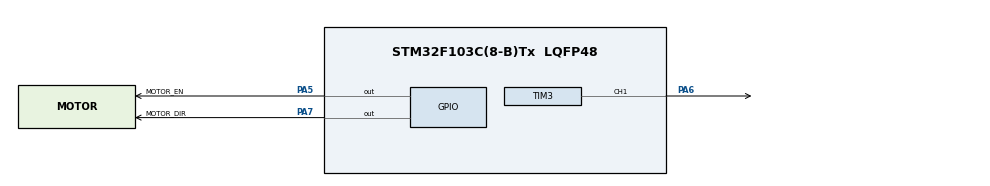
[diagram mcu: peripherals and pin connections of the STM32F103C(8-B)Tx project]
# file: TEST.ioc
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Mcu.Family=STM32F1
Mcu.Name=STM32F103C(8-B)Tx
Mcu.Package=LQFP48
NVIC.PriorityGroup=NVIC_PRIORITYGROUP_4
NVIC.TIM3_IRQn=true\:0\:0\:false\:false\:true\:true\:true\:true
PA13.Mode=Serial_Wire
PA13.Signal=SYS_JTMS-SWDIO
PA14.Mode=Serial_Wire
PA14.Signal=SYS_JTCK-SWCLK
PA5.GPIO_Label=MOTOR_EN
PA5.GPIO_Speed=GPIO_SPEED_FREQ_HIGH
PA5.Signal=GPIO_Output
PA6.Signal=S_TIM3_CH1
PA7.GPIO_Label=MOTOR_DIR
PA7.GPIO_Speed=GPIO_SPEED_FREQ_HIGH
PA7.Signal=GPIO_Output
ProjectManager.HeapSize=0x200
ProjectManager.StackSize=0x400
ProjectManager.TargetToolchain=CMake
RCC.APB1Freq_Value=8000000
RCC.APB2Freq_Value=8000000
SH.S_TIM3_CH1.0=TIM3_CH1,PWM Generation1 CH1
TIM3.Channel-PWM\ Generation1\ CH1=TIM_CHANNEL_1
TIM3.Period=10000
TIM3.Prescaler=71
VP_TIM3_VS_ClockSourceINT.Mode=Internal
board=custom

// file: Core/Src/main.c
/* USER CODE BEGIN Header */
/**
  ******************************************************************************
  * @file           : main.c
  * @brief          : Main program body
  ******************************************************************************
  * @attention
  *
  * Copyright (c) 2026 STMicroelectronics.
  * All rights reserved.
  *
  * This software is licensed under terms that can be found in the LICENSE file
  * in the root directory of this software component.
  * If no LICENSE file comes with this software, it is provided AS-IS.
  *
  ******************************************************************************
  */
/* USER CODE END Header */
#include "main.h"
#include "stepper_motor.h"

/* USER CODE BEGIN PD */
extern volatile uint8_t is_motor_running;
/* USER CODE END PD */

TIM_HandleTypeDef htim3;

void SystemClock_Config(void);
static void MX_GPIO_Init(void);
static void MX_TIM3_Init(void);

int main(void)
{

  /* MCU Configuration--------------------------------------------------------*/

  /* Reset of all peripherals, Initializes the Flash interface and the Systick. */
  HAL_Init();

  /* Configure the system clock */
  SystemClock_Config();

  /* Initialize all configured peripherals */
  MX_GPIO_Init();
  MX_TIM3_Init();
  /* USER CODE BEGIN 2 */
  Motor_Stop();
  HAL_Delay(1000);
  /* USER CODE END 2 */

  /* Infinite loop */
  /* USER CODE BEGIN WHILE */
  while (1)
  {
    // --- 第 1 次转动：顺时针转 2 圈 (720 度) ---
    // 速度设定 360 度/秒，那么 2 圈大约跑 2 秒
    Motor_Speed_Dir_Angle(360.0f, 1, 720.0f);

    // 等待电机自动停止 (is_motor_running 被中断清 0)
    // 加上 100ms 的额外保护，避免刚好卡在临界点
    while (is_motor_running) {
        HAL_Delay(10);
    }
    HAL_Delay(100);

    // --- 停顿 2 秒 ---
    Motor_Stop(); // 确保完全停止
    HAL_Delay(2000);

    // --- 第 2 次转动：逆时针转 2 圈 (720 度) ---
    Motor_Speed_Dir_Angle(360.0f, 0, 720.0f);

    // 再次等待转动结束
    while (is_motor_running) {
        HAL_Delay(10);
    }
    HAL_Delay(100);

    // --- 停顿 2 秒，然后自动进入下一次循环 ---
    Motor_Stop();
    HAL_Delay(2000);
    /* USER CODE END WHILE */

  }
}

void SystemClock_Config(void)
{
  RCC_OscInitTypeDef RCC_OscInitStruct = {0};
  RCC_ClkInitTypeDef RCC_ClkInitStruct = {0};

  /** Initializes the RCC Oscillators according to the specified parameters
  * in the RCC_OscInitTypeDef structure.
  */
  RCC_OscInitStruct.OscillatorType = RCC_OSCILLATORTYPE_HSI;
  RCC_OscInitStruct.HSIState = RCC_HSI_ON;
  RCC_OscInitStruct.HSICalibrationValue = RCC_HSICALIBRATION_DEFAULT;
  RCC_OscInitStruct.PLL.PLLState = RCC_PLL_NONE;
  if (HAL_RCC_OscConfig(&RCC_OscInitStruct) != HAL_OK)
  {
    Error_Handler();
  }

  /** Initializes the CPU, AHB and APB buses clocks
  */
  RCC_ClkInitStruct.ClockType = RCC_CLOCKTYPE_HCLK|RCC_CLOCKTYPE_SYSCLK
                              |RCC_CLOCKTYPE_PCLK1|RCC_CLOCKTYPE_PCLK2;
  RCC_ClkInitStruct.SYSCLKSource = RCC_SYSCLKSOURCE_HSI;
  RCC_ClkInitStruct.AHBCLKDivider = RCC_SYSCLK_DIV1;
  RCC_ClkInitStruct.APB1CLKDivider = RCC_HCLK_DIV1;
  RCC_ClkInitStruct.APB2CLKDivider = RCC_HCLK_DIV1;

  if (HAL_RCC_ClockConfig(&RCC_ClkInitStruct, FLASH_LATENCY_0) != HAL_OK)
  {
    Error_Handler();
  }
}

static void MX_TIM3_Init(void)
{

  TIM_ClockConfigTypeDef sClockSourceConfig = {0};
  TIM_MasterConfigTypeDef sMasterConfig = {0};
  TIM_OC_InitTypeDef sConfigOC = {0};

  htim3.Instance = TIM3;
  htim3.Init.Prescaler = 71;
  htim3.Init.CounterMode = TIM_COUNTERMODE_UP;
  htim3.Init.Period = 10000;
  htim3.Init.ClockDivision = TIM_CLOCKDIVISION_DIV1;
  htim3.Init.AutoReloadPreload = TIM_AUTORELOAD_PRELOAD_DISABLE;
  if (HAL_TIM_Base_Init(&htim3) != HAL_OK)
  {
    Error_Handler();
  }
  sClockSourceConfig.ClockSource = TIM_CLOCKSOURCE_INTERNAL;
  if (HAL_TIM_ConfigClockSource(&htim3, &sClockSourceConfig) != HAL_OK)
  {
    Error_Handler();
  }
  if (HAL_TIM_PWM_Init(&htim3) != HAL_OK)
  {
    Error_Handler();
  }
  sMasterConfig.MasterOutputTrigger = TIM_TRGO_RESET;
  sMasterConfig.MasterSlaveMode = TIM_MASTERSLAVEMODE_DISABLE;
  if (HAL_TIMEx_MasterConfigSynchronization(&htim3, &sMasterConfig) != HAL_OK)
  {
    Error_Handler();
  }
  sConfigOC.OCMode = TIM_OCMODE_PWM1;
  sConfigOC.Pulse = 0;
  sConfigOC.OCPolarity = TIM_OCPOLARITY_HIGH;
  sConfigOC.OCFastMode = TIM_OCFAST_DISABLE;
  if (HAL_TIM_PWM_ConfigChannel(&htim3, &sConfigOC, TIM_CHANNEL_1) != HAL_OK)
  {
    Error_Handler();
  }
  HAL_TIM_MspPostInit(&htim3);

}

static void MX_GPIO_Init(void)
{
  GPIO_InitTypeDef GPIO_InitStruct = {0};

  /* GPIO Ports Clock Enable */
  __HAL_RCC_GPIOA_CLK_ENABLE();

  /*Configure GPIO pin Output Level */
  HAL_GPIO_WritePin(GPIOA, MOTOR_EN_Pin|MOTOR_DIR_Pin, GPIO_PIN_RESET);

  /*Configure GPIO pins : MOTOR_EN_Pin MOTOR_DIR_Pin */
  GPIO_InitStruct.Pin = MOTOR_EN_Pin|MOTOR_DIR_Pin;
  GPIO_InitStruct.Mode = GPIO_MODE_OUTPUT_PP;
  GPIO_InitStruct.Pull = GPIO_NOPULL;
  GPIO_InitStruct.Speed = GPIO_SPEED_FREQ_HIGH;
  HAL_GPIO_Init(GPIOA, &GPIO_InitStruct);

}

void Error_Handler(void)
{
  __disable_irq();
  while (1)
  {
  }
}
